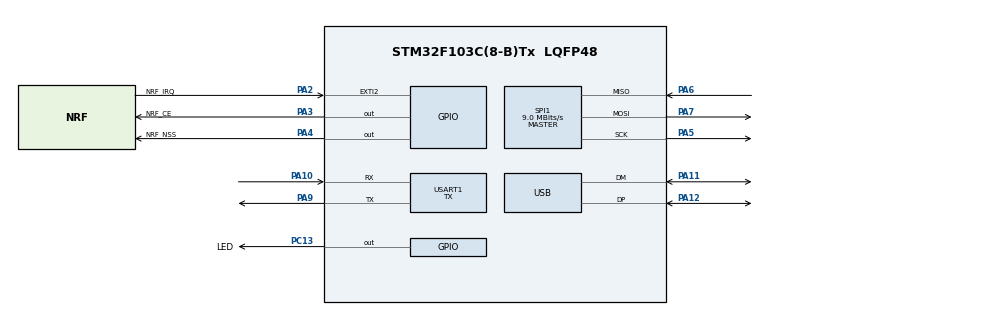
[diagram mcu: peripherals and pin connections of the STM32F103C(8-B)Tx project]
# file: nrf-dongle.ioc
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Dma.Request0=USART1_TX
Dma.Request1=SPI1_RX
Dma.Request2=SPI1_TX
Dma.SPI1_RX.1.Direction=DMA_PERIPH_TO_MEMORY
Dma.SPI1_RX.1.Instance=DMA1_Channel2
Dma.SPI1_RX.1.MemDataAlignment=DMA_MDATAALIGN_BYTE
Dma.SPI1_RX.1.MemInc=DMA_MINC_ENABLE
Dma.SPI1_RX.1.Mode=DMA_NORMAL
Dma.SPI1_RX.1.PeriphDataAlignment=DMA_PDATAALIGN_BYTE
Dma.SPI1_RX.1.PeriphInc=DMA_PINC_DISABLE
Dma.SPI1_RX.1.Priority=DMA_PRIORITY_HIGH
Dma.SPI1_TX.2.Direction=DMA_MEMORY_TO_PERIPH
Dma.SPI1_TX.2.Instance=DMA1_Channel3
Dma.SPI1_TX.2.MemDataAlignment=DMA_MDATAALIGN_BYTE
Dma.SPI1_TX.2.MemInc=DMA_MINC_ENABLE
Dma.SPI1_TX.2.Mode=DMA_NORMAL
Dma.SPI1_TX.2.PeriphDataAlignment=DMA_PDATAALIGN_BYTE
Dma.SPI1_TX.2.PeriphInc=DMA_PINC_DISABLE
Dma.SPI1_TX.2.Priority=DMA_PRIORITY_HIGH
Dma.USART1_TX.0.Direction=DMA_MEMORY_TO_PERIPH
Dma.USART1_TX.0.Instance=DMA1_Channel4
Dma.USART1_TX.0.MemDataAlignment=DMA_MDATAALIGN_BYTE
Dma.USART1_TX.0.MemInc=DMA_MINC_ENABLE
Dma.USART1_TX.0.Mode=DMA_NORMAL
Dma.USART1_TX.0.PeriphDataAlignment=DMA_PDATAALIGN_BYTE
Dma.USART1_TX.0.PeriphInc=DMA_PINC_DISABLE
Dma.USART1_TX.0.Priority=DMA_PRIORITY_LOW
Mcu.Family=STM32F1
Mcu.Name=STM32F103C(8-B)Tx
Mcu.Package=LQFP48
NVIC.DMA1_Channel2_IRQn=true\:0\:0\:false\:false\:true\:false
NVIC.DMA1_Channel3_IRQn=true\:0\:0\:false\:false\:true\:false
NVIC.DMA1_Channel4_IRQn=true\:0\:0\:false\:false\:true\:false
NVIC.PriorityGroup=NVIC_PRIORITYGROUP_4
NVIC.USB_LP_CAN1_RX0_IRQn=true\:0\:0\:false\:false\:true\:false
PA10.Mode=Asynchronous
PA10.Signal=USART1_RX
PA11.Mode=Device
PA11.Signal=USB_DM
PA12.Mode=Device
PA12.Signal=USB_DP
PA2.GPIO_Label=NRF_IRQ
PA2.Signal=GPXTI2
PA3.GPIO_Label=NRF_CE
PA3.Signal=GPIO_Output
PA4.GPIO_Label=NRF_NSS
PA4.Signal=GPIO_Output
PA5.Mode=Full_Duplex_Master
PA5.Signal=SPI1_SCK
PA6.Mode=Full_Duplex_Master
PA6.Signal=SPI1_MISO
PA7.Mode=Full_Duplex_Master
PA7.Signal=SPI1_MOSI
PA9.Mode=Asynchronous
PA9.Signal=USART1_TX
PC13-TAMPER-RTC.GPIO_Label=LED
PC13-TAMPER-RTC.Signal=GPIO_Output
PD0-OSC_IN.Mode=HSE-External-Oscillator
PD0-OSC_IN.Signal=RCC_OSC_IN
PD1-OSC_OUT.Mode=HSE-External-Oscillator
PD1-OSC_OUT.Signal=RCC_OSC_OUT
ProjectManager.HeapSize=0x200
ProjectManager.StackSize=0x400
ProjectManager.TargetToolchain=Makefile
RCC.AHBFreq_Value=72000000
RCC.APB1CLKDivider=RCC_HCLK_DIV2
RCC.APB1Freq_Value=36000000
RCC.APB1TimFreq_Value=72000000
RCC.APB2Freq_Value=72000000
RCC.APB2TimFreq_Value=72000000
RCC.HCLKFreq_Value=72000000
RCC.PLLMUL=RCC_PLL_MUL9
RCC.SYSCLKFreq_VALUE=72000000
RCC.SYSCLKSource=RCC_SYSCLKSOURCE_PLLCLK
RCC.USBFreq_Value=48000000
RCC.USBPrescaler=RCC_USBCLKSOURCE_PLL_DIV1_5
SPI1.BaudRatePrescaler=SPI_BAUDRATEPRESCALER_8
SPI1.CLKPhase=SPI_PHASE_2EDGE
SPI1.CalculateBaudRate=9.0 MBits/s
SPI1.Direction=SPI_DIRECTION_2LINES
SPI1.Mode=SPI_MODE_MASTER
SPI1.VirtualType=VM_MASTER
USART1.Mode=MODE_TX
USART1.VirtualMode=VM_ASYNC
USB_DEVICE.CLASS_NAME_FS=CDC
USB_DEVICE.PID_CDC_FS=19553
USB_DEVICE.PRODUCT_STRING_CDC_FS=GEX wireless dongle
USB_DEVICE.USBD_MAX_STR_DESC_SIZ=64
USB_DEVICE.VID=4617
USB_DEVICE.VirtualMode=Cdc
USB_DEVICE.VirtualModeFS=Cdc_FS
VP_SYS_VS_ND.Mode=No_Debug
VP_USB_DEVICE_VS_USB_DEVICE_CDC_FS.Mode=CDC_FS
board=nrf-dongle

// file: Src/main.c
/**
  ******************************************************************************
  * @file           : main.c
  * @brief          : Main program body
  ******************************************************************************
  * This notice applies to any and all portions of this file
  * that are not between comment pairs USER CODE BEGIN and
  * USER CODE END. Other portions of this file, whether
  * inserted by the user or by software development tools
  * are owned by their respective copyright owners.
  *
  * Copyright (c) 2018 STMicroelectronics International N.V.
  * All rights reserved.
  *
  * Redistribution and use in source and binary forms, with or without
  * modification, are permitted, provided that the following conditions are met:
  *
  * 1. Redistribution of source code must retain the above copyright notice,
  *    this list of conditions and the following disclaimer.
  * 2. Redistributions in binary form must reproduce the above copyright notice,
  *    this list of conditions and the following disclaimer in the documentation
  *    and/or other materials provided with the distribution.
  * 3. Neither the name of STMicroelectronics nor the names of other
  *    contributors to this software may be used to endorse or promote products
  *    derived from this software without specific written permission.
  * 4. This software, including modifications and/or derivative works of this
  *    software, must execute solely and exclusively on microcontroller or
  *    microprocessor devices manufactured by or for STMicroelectronics.
  * 5. Redistribution and use of this software other than as permitted under
  *    this license is void and will automatically terminate your rights under
  *    this license.
  *
  * THIS SOFTWARE IS PROVIDED BY STMICROELECTRONICS AND CONTRIBUTORS "AS IS"
  * AND ANY EXPRESS, IMPLIED OR STATUTORY WARRANTIES, INCLUDING, BUT NOT
  * LIMITED TO, THE IMPLIED WARRANTIES OF MERCHANTABILITY, FITNESS FOR A
  * PARTICULAR PURPOSE AND NON-INFRINGEMENT OF THIRD PARTY INTELLECTUAL PROPERTY
  * RIGHTS ARE DISCLAIMED TO THE FULLEST EXTENT PERMITTED BY LAW. IN NO EVENT
  * SHALL STMICROELECTRONICS OR CONTRIBUTORS BE LIABLE FOR ANY DIRECT, INDIRECT,
  * INCIDENTAL, SPECIAL, EXEMPLARY, OR CONSEQUENTIAL DAMAGES (INCLUDING, BUT NOT
  * LIMITED TO, PROCUREMENT OF SUBSTITUTE GOODS OR SERVICES; LOSS OF USE, DATA,
  * OR PROFITS; OR BUSINESS INTERRUPTION) HOWEVER CAUSED AND ON ANY THEORY OF
  * LIABILITY, WHETHER IN CONTRACT, STRICT LIABILITY, OR TORT (INCLUDING
  * NEGLIGENCE OR OTHERWISE) ARISING IN ANY WAY OUT OF THE USE OF THIS SOFTWARE,
  * EVEN IF ADVISED OF THE POSSIBILITY OF SUCH DAMAGE.
  *
  ******************************************************************************
  */
#include "main.h"
#include "stm32f1xx_hal.h"
#include "dma.h"
#include "spi.h"
#include "usart.h"
#include "usb_device.h"
#include "gpio.h"
#include "debug.h"
#include "gex_gateway.h"
#include "msg_queue.h"
#include "usbd_cdc_if.h"

/* USER CODE BEGIN Includes */

uint32_t led_tx_countdown = 0;
uint32_t led_rx_countdown = 0;

/* USER CODE END Includes */

/* USER CODE BEGIN PV */
/* Private variables ---------------------------------------------------------*/

/* USER CODE END PV */

void SystemClock_Config(void);

/* USER CODE BEGIN PFP */
/* Private function prototypes -----------------------------------------------*/

/* USER CODE END PFP */

extern void EXTI1_IRQHandler(void);

int main(void)
{

    /* MCU Configuration----------------------------------------------------------*/

    /* Reset of all peripherals, Initializes the Flash interface and the Systick. */
    HAL_Init();

    /* Configure the system clock */
    SystemClock_Config();

    LL_APB2_GRP1_EnableClock(LL_APB2_GRP1_PERIPH_GPIOC);
    LL_APB2_GRP1_EnableClock(LL_APB2_GRP1_PERIPH_GPIOD);
    LL_APB2_GRP1_EnableClock(LL_APB2_GRP1_PERIPH_GPIOB);
    LL_APB2_GRP1_EnableClock(LL_APB2_GRP1_PERIPH_GPIOA);

    /* Initialize all configured peripherals */
    MX_GPIO_Init();
    MX_DMA_Init();
    MX_USB_DEVICE_Init();
    MX_SPI1_Init();
    MX_USART1_UART_Init();
    /* USER CODE BEGIN 2 */

    // give juice to the nrf module
    LL_GPIO_ResetOutputPin(NRF_RESET_GPIO_Port, NRF_RESET_Pin);
    /* USER CODE END 2 */

    gw_setup_radio();
    mq_init(&usb_inq);

    // re-enumerate USB
    LL_GPIO_SetOutputPin(RENUM_GPIO_Port, RENUM_Pin);
    LL_mDelay(100);
    LL_GPIO_ResetOutputPin(RENUM_GPIO_Port, RENUM_Pin);

    dbg("Main loop starts.");
    /* Infinite loop */
    /* USER CODE BEGIN WHILE */
    uint32_t cnt = 0;
    uint8_t buff[MQ_SLOT_LEN];

    while (1) {
        cnt++;
        if (cnt > 1400000) {
            LL_GPIO_SetOutputPin(LED_GPIO_Port, LED1_Pin);
        }
        if (cnt > 1500000) {
            LL_GPIO_ResetOutputPin(LED_GPIO_Port, LED1_Pin);
            cnt = 0;
        }

        if (led_tx_countdown > 0) {
            if (--led_tx_countdown == 0) {
                LL_GPIO_ResetOutputPin(LED_GPIO_Port, LEDTX_Pin);
            }
        }

        if (led_rx_countdown > 0) {
            if (--led_rx_countdown == 0) {
                LL_GPIO_ResetOutputPin(LED_GPIO_Port, LEDRX_Pin);
            }
        }

        if (mq_can_read(&usb_inq)) {
            if (!usb_tx_busy) {
                mq_read(&usb_inq, buff);
                CDC_Transmit_FS(buff, MQ_SLOT_LEN);
            }
        }
    }
    /* USER CODE END 3 */

}

void SystemClock_Config(void)
{

    LL_FLASH_SetLatency(LL_FLASH_LATENCY_2);

    if (LL_FLASH_GetLatency() != LL_FLASH_LATENCY_2) {
        Error_Handler();
    }
    LL_RCC_HSE_Enable();

    /* Wait till HSE is ready */
    while (LL_RCC_HSE_IsReady() != 1) {

    }
    LL_RCC_PLL_ConfigDomain_SYS(LL_RCC_PLLSOURCE_HSE_DIV_1, LL_RCC_PLL_MUL_9);

    LL_RCC_PLL_Enable();

    /* Wait till PLL is ready */
    while (LL_RCC_PLL_IsReady() != 1) {

    }
    LL_RCC_SetAHBPrescaler(LL_RCC_SYSCLK_DIV_1);

    LL_RCC_SetAPB1Prescaler(LL_RCC_APB1_DIV_2);

    LL_RCC_SetAPB2Prescaler(LL_RCC_APB2_DIV_1);

    LL_RCC_SetSysClkSource(LL_RCC_SYS_CLKSOURCE_PLL);

    /* Wait till System clock is ready */
    while (LL_RCC_GetSysClkSource() != LL_RCC_SYS_CLKSOURCE_STATUS_PLL) {

    }
    LL_Init1msTick(72000000);

    LL_SYSTICK_SetClkSource(LL_SYSTICK_CLKSOURCE_HCLK);

    LL_SetSystemCoreClock(72000000);

    LL_RCC_SetUSBClockSource(LL_RCC_USB_CLKSOURCE_PLL_DIV_1_5);

    /* SysTick_IRQn interrupt configuration */
    NVIC_SetPriority(SysTick_IRQn, NVIC_EncodePriority(NVIC_GetPriorityGrouping(), 0, 0));
}

void _Error_Handler(char *file, int line)
{
    while (1) {
    }
}

/************************ (C) COPYRIGHT STMicroelectronics *****END OF FILE****/
